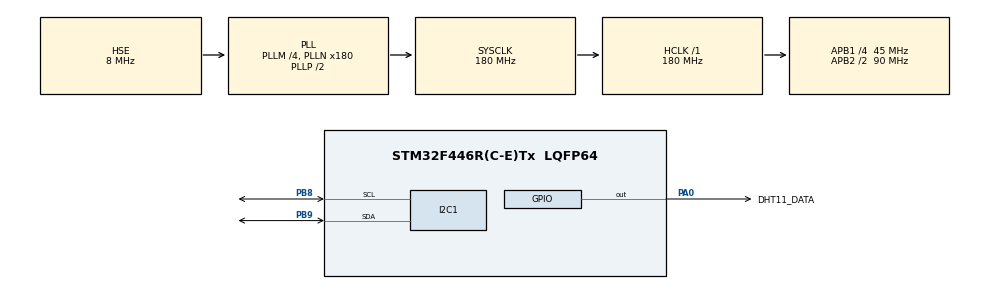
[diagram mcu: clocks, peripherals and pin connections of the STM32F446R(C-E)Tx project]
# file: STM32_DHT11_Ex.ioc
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Mcu.Family=STM32F4
Mcu.Name=STM32F446R(C-E)Tx
Mcu.Package=LQFP64
NVIC.PriorityGroup=NVIC_PRIORITYGROUP_4
PA0-WKUP.GPIO_Label=DHT11_DATA
PA0-WKUP.GPIO_ModeDefaultOutputPP=GPIO_MODE_OUTPUT_PP
PA0-WKUP.GPIO_PuPd=GPIO_NOPULL
PA0-WKUP.GPIO_Speed=GPIO_SPEED_FREQ_VERY_HIGH
PA0-WKUP.PinState=GPIO_PIN_SET
PA0-WKUP.Signal=GPIO_Output
PB8.Mode=I2C
PB8.Signal=I2C1_SCL
PB9.Mode=I2C
PB9.Signal=I2C1_SDA
PH0-OSC_IN.Mode=HSE-External-Oscillator
PH0-OSC_IN.Signal=RCC_OSC_IN
PH1-OSC_OUT.Mode=HSE-External-Oscillator
PH1-OSC_OUT.Signal=RCC_OSC_OUT
ProjectManager.HeapSize=0x200
ProjectManager.StackSize=0x400
ProjectManager.TargetToolchain=STM32CubeIDE
RCC.AHBFreq_Value=180000000
RCC.APB1CLKDivider=RCC_HCLK_DIV4
RCC.APB1Freq_Value=45000000
RCC.APB1TimFreq_Value=90000000
RCC.APB2CLKDivider=RCC_HCLK_DIV2
RCC.APB2Freq_Value=90000000
RCC.APB2TimFreq_Value=180000000
RCC.CortexFreq_Value=180000000
RCC.HCLKFreq_Value=180000000
RCC.HSE_VALUE=8000000
RCC.PLLM=4
RCC.PLLN=180
RCC.PLLSourceVirtual=RCC_PLLSOURCE_HSE
RCC.SYSCLKFreq_VALUE=180000000
RCC.SYSCLKSource=RCC_SYSCLKSOURCE_PLLCLK
RCC.USBFreq_Value=180000000
RCC.VCOOutputFreq_Value=360000000
TIM6.Period=0xffff-1
TIM6.Prescaler=90-1
VP_TIM6_VS_ClockSourceINT.Mode=Enable_Timer
board=custom

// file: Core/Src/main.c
/* USER CODE BEGIN Header */
/**
  ******************************************************************************
  * @file           : main.c
  * @brief          : Main program body
  ******************************************************************************
  * @attention
  *
  * <h2><center>&copy; Copyright (c) 2020 STMicroelectronics.
  * All rights reserved.</center></h2>
  *
  * This software component is licensed by ST under BSD 3-Clause license,
  * the "License"; You may not use this file except in compliance with the
  * License. You may obtain a copy of the License at:
  *                        opensource.org/licenses/BSD-3-Clause
  *
  ******************************************************************************
  */
/* USER CODE END Header */
#include "main.h"

/* USER CODE BEGIN Includes */
#include <stdio.h>
#include"i2c-lcd.h"
/* USER CODE END Includes */

/* USER CODE BEGIN PD */
#define OUTPUT 1
#define INPUT 0
/* USER CODE END PD */

I2C_HandleTypeDef hi2c1;

TIM_HandleTypeDef htim6;

/* USER CODE BEGIN PV */
uint32_t mTime1=0,mTime2=0,mData[40],mBit=0;
uint8_t humVal=0,tempVal=0,parityVal=0;
float humVal_frac=0,tempVal_frac=0;
char sendData[40];
/* USER CODE END PV */

void SystemClock_Config(void);
static void MX_GPIO_Init(void);
static void MX_TIM6_Init(void);
static void MX_I2C1_Init(void);

/* USER CODE BEGIN 0 */

void us_Delay(uint16_t time)
{
	uint16_t initTime = (uint16_t)__HAL_TIM_GET_COUNTER(&htim6);				//get initial time
		while(((uint16_t)__HAL_TIM_GET_COUNTER(&htim6)-initTime) < time){		//wait until (time now - inital time == 0)
		}
}

//set DHT pin direction with given parameter
void set_gpio_mode(uint8_t pMode)
{
	GPIO_InitTypeDef GPIO_InitStruct = {0};

	//if direction parameter OUTPUT
	if(pMode == OUTPUT)
	{
	  GPIO_InitStruct.Pin = DHT11_DATA_Pin;
	  GPIO_InitStruct.Mode = GPIO_MODE_OUTPUT_PP;
	  GPIO_InitStruct.Pull = GPIO_NOPULL;
	  GPIO_InitStruct.Speed = GPIO_SPEED_FREQ_VERY_HIGH;
	  HAL_GPIO_Init(DHT11_DATA_GPIO_Port, &GPIO_InitStruct);

	}else if(pMode == INPUT)   //else if direction parameter INPUT
	{
	  GPIO_InitStruct.Pin = DHT11_DATA_Pin;
	  GPIO_InitStruct.Mode = GPIO_MODE_INPUT;
	  GPIO_InitStruct.Pull = GPIO_NOPULL;
	  GPIO_InitStruct.Speed = GPIO_SPEED_FREQ_VERY_HIGH;
	  HAL_GPIO_Init(DHT11_DATA_GPIO_Port, &GPIO_InitStruct);
	}
	else
		Error_Handler();

}
void DHT11_Start()
{
	//start communication
	set_gpio_mode(OUTPUT);			//set pin direction as output
	HAL_GPIO_WritePin(DHT11_DATA_GPIO_Port, DHT11_DATA_Pin, GPIO_PIN_RESET);
	HAL_Delay(20);					//wait 20 ms in Low state
	set_gpio_mode(INPUT);			//set pin direction as input
}
void DHT11_check()
{
	//check dht answer
		__HAL_TIM_SET_COUNTER(&htim6, 0);				//set timer counter to zero
		while(HAL_GPIO_ReadPin(DHT11_DATA_GPIO_Port, DHT11_DATA_Pin) == GPIO_PIN_SET)
			if((uint16_t)__HAL_TIM_GET_COUNTER(&htim6) > 500)
				return 0;

		__HAL_TIM_SET_COUNTER(&htim6, 0);
		while(HAL_GPIO_ReadPin(DHT11_DATA_GPIO_Port, DHT11_DATA_Pin) == GPIO_PIN_RESET)
			if((uint16_t)__HAL_TIM_GET_COUNTER(&htim6) > 500)
				return 0;

		mTime1 = (uint16_t)__HAL_TIM_GET_COUNTER(&htim6);
		__HAL_TIM_SET_COUNTER(&htim6, 0);
		while(HAL_GPIO_ReadPin(DHT11_DATA_GPIO_Port, DHT11_DATA_Pin) == GPIO_PIN_SET)
			if((uint16_t)__HAL_TIM_GET_COUNTER(&htim6) > 500)
				return 0;
		mTime2 = (uint16_t)__HAL_TIM_GET_COUNTER(&htim6);

		//if answer is wrong return
		if(mTime1 < 75 && mTime1 > 85 && mTime2 < 75 && mTime2 > 85)
		{
			return 0;
		}

}
void DHT11_read()
	{
	for (int j = 0; j < 40; j++) {
		__HAL_TIM_SET_COUNTER(&htim6, 0);
		while (HAL_GPIO_ReadPin(DHT11_DATA_GPIO_Port, DHT11_DATA_Pin)
				== GPIO_PIN_RESET)
			if ((uint16_t) __HAL_TIM_GET_COUNTER(&htim6) > 500)
				return 0;

		__HAL_TIM_SET_COUNTER(&htim6, 0);

		while (HAL_GPIO_ReadPin(DHT11_DATA_GPIO_Port, DHT11_DATA_Pin)
				== GPIO_PIN_SET)
			if ((uint16_t) __HAL_TIM_GET_COUNTER(&htim6) > 500)
				return 0;

		mTime1 = (uint16_t) __HAL_TIM_GET_COUNTER(&htim6);

		//check pass time in high state
		//if pass time 25uS set as LOW
		if (mTime1 > 20 && mTime1 < 30) {
			mBit = 0;
		} else if (mTime1 > 60 && mTime1 < 80) //if pass time 70 uS set as HIGH
				{
			mBit = 1;
		}

		//set i th data in data buffer
		mData[j] = mBit;

	}
}
void DHT11_conversion()
{
	uint8_t i=0,check=0,j=0;
	for (i = 0; i < 40; i++)
	{
			if (i < 8) 					//get humid value from data buffer
			{
				j=7-i;
				check = mData[7-j];
				check = check << j;
				humVal += check;
			}

			else if (i < 16 && i >= 8) //get humid value fractional part from data buffer
			{
				j = 15-i;
				check = mData[15-j];
				check = check << j;
				humVal_frac += check;
			}
			else if (i < 24 && i>=16)	//get temp value from data buffer
			{
				j = 23 - i;
				check = mData[23-j];
				check = check << (j);
				tempVal += check;
			}
			else if (i<32 && i >= 24)	//get temp value fractional part from data buffer
			{
				j = 31-i;
				check = mData[31-j];
				check = check << j;
				tempVal_frac += check;
			}
			else if (i>=32)	//get parity value from data buffer
			{
				j = 39-i;
				check = mData[39-j];
				check = check << j;
				parityVal += check;
			}
			else
				Error_Handler();
	}
	tempVal_frac/=10;
	humVal_frac/=10;
	tempVal_frac+=tempVal;
	humVal_frac+=humVal;

}

/* USER CODE END 0 */

int main(void)
{

  /* MCU Configuration--------------------------------------------------------*/

  /* Reset of all peripherals, Initializes the Flash interface and the Systick. */
  HAL_Init();

  /* Configure the system clock */
  SystemClock_Config();

  /* Initialize all configured peripherals */
  MX_GPIO_Init();
  MX_TIM6_Init();
  MX_I2C1_Init();
  /* USER CODE BEGIN 2 */
  HAL_TIM_Base_Start(&htim6);
  DHT11_Start();
  DHT11_check();
  DHT11_read();
  DHT11_conversion();
  lcd_init();
  lcd_put_cur(0, 0);
  sprintf(sendData,"Temperature:%.2fC",tempVal_frac);
  lcd_send_string(sendData);
  lcd_put_cur(1, 0);
  sprintf(sendData,"Humidity:%.2f%",humVal_frac);
  lcd_send_string(sendData);

  /* USER CODE END 2 */

  /* Infinite loop */
  while (1)
  {

  }
}

void SystemClock_Config(void)
{
  RCC_OscInitTypeDef RCC_OscInitStruct = {0};
  RCC_ClkInitTypeDef RCC_ClkInitStruct = {0};

  /** Configure the main internal regulator output voltage
  */
  __HAL_RCC_PWR_CLK_ENABLE();
  __HAL_PWR_VOLTAGESCALING_CONFIG(PWR_REGULATOR_VOLTAGE_SCALE1);
  /** Initializes the RCC Oscillators according to the specified parameters
  * in the RCC_OscInitTypeDef structure.
  */
  RCC_OscInitStruct.OscillatorType = RCC_OSCILLATORTYPE_HSE;
  RCC_OscInitStruct.HSEState = RCC_HSE_ON;
  RCC_OscInitStruct.PLL.PLLState = RCC_PLL_ON;
  RCC_OscInitStruct.PLL.PLLSource = RCC_PLLSOURCE_HSE;
  RCC_OscInitStruct.PLL.PLLM = 4;
  RCC_OscInitStruct.PLL.PLLN = 180;
  RCC_OscInitStruct.PLL.PLLP = RCC_PLLP_DIV2;
  RCC_OscInitStruct.PLL.PLLQ = 2;
  RCC_OscInitStruct.PLL.PLLR = 2;
  if (HAL_RCC_OscConfig(&RCC_OscInitStruct) != HAL_OK)
  {
    Error_Handler();
  }
  /** Activate the Over-Drive mode
  */
  if (HAL_PWREx_EnableOverDrive() != HAL_OK)
  {
    Error_Handler();
  }
  /** Initializes the CPU, AHB and APB buses clocks
  */
  RCC_ClkInitStruct.ClockType = RCC_CLOCKTYPE_HCLK|RCC_CLOCKTYPE_SYSCLK
                              |RCC_CLOCKTYPE_PCLK1|RCC_CLOCKTYPE_PCLK2;
  RCC_ClkInitStruct.SYSCLKSource = RCC_SYSCLKSOURCE_PLLCLK;
  RCC_ClkInitStruct.AHBCLKDivider = RCC_SYSCLK_DIV1;
  RCC_ClkInitStruct.APB1CLKDivider = RCC_HCLK_DIV4;
  RCC_ClkInitStruct.APB2CLKDivider = RCC_HCLK_DIV2;

  if (HAL_RCC_ClockConfig(&RCC_ClkInitStruct, FLASH_LATENCY_5) != HAL_OK)
  {
    Error_Handler();
  }
}

static void MX_I2C1_Init(void)
{

  hi2c1.Instance = I2C1;
  hi2c1.Init.ClockSpeed = 100000;
  hi2c1.Init.DutyCycle = I2C_DUTYCYCLE_2;
  hi2c1.Init.OwnAddress1 = 0;
  hi2c1.Init.AddressingMode = I2C_ADDRESSINGMODE_7BIT;
  hi2c1.Init.DualAddressMode = I2C_DUALADDRESS_DISABLE;
  hi2c1.Init.OwnAddress2 = 0;
  hi2c1.Init.GeneralCallMode = I2C_GENERALCALL_DISABLE;
  hi2c1.Init.NoStretchMode = I2C_NOSTRETCH_DISABLE;
  if (HAL_I2C_Init(&hi2c1) != HAL_OK)
  {
    Error_Handler();
  }

}

static void MX_TIM6_Init(void)
{

  TIM_MasterConfigTypeDef sMasterConfig = {0};

  htim6.Instance = TIM6;
  htim6.Init.Prescaler = 90-1;
  htim6.Init.CounterMode = TIM_COUNTERMODE_UP;
  htim6.Init.Period = 0xffff-1;
  htim6.Init.AutoReloadPreload = TIM_AUTORELOAD_PRELOAD_DISABLE;
  if (HAL_TIM_Base_Init(&htim6) != HAL_OK)
  {
    Error_Handler();
  }
  sMasterConfig.MasterOutputTrigger = TIM_TRGO_RESET;
  sMasterConfig.MasterSlaveMode = TIM_MASTERSLAVEMODE_DISABLE;
  if (HAL_TIMEx_MasterConfigSynchronization(&htim6, &sMasterConfig) != HAL_OK)
  {
    Error_Handler();
  }

}

static void MX_GPIO_Init(void)
{
  GPIO_InitTypeDef GPIO_InitStruct = {0};

  /* GPIO Ports Clock Enable */
  __HAL_RCC_GPIOH_CLK_ENABLE();
  __HAL_RCC_GPIOA_CLK_ENABLE();
  __HAL_RCC_GPIOB_CLK_ENABLE();

  /*Configure GPIO pin Output Level */
  HAL_GPIO_WritePin(DHT11_DATA_GPIO_Port, DHT11_DATA_Pin, GPIO_PIN_SET);

  /*Configure GPIO pin : DHT11_DATA_Pin */
  GPIO_InitStruct.Pin = DHT11_DATA_Pin;
  GPIO_InitStruct.Mode = GPIO_MODE_OUTPUT_PP;
  GPIO_InitStruct.Pull = GPIO_NOPULL;
  GPIO_InitStruct.Speed = GPIO_SPEED_FREQ_VERY_HIGH;
  HAL_GPIO_Init(DHT11_DATA_GPIO_Port, &GPIO_InitStruct);

}

void Error_Handler(void)
{
}

/************************ (C) COPYRIGHT STMicroelectronics *****END OF FILE****/
